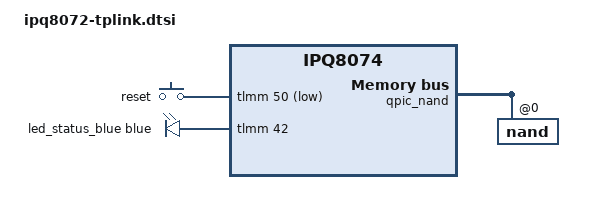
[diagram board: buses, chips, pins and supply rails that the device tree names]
// SPDX-License-Identifier: GPL-2.0-or-later OR MIT

#include "ipq8074.dtsi"
#include "ipq8074-ess.dtsi"
#include "ipq8074-nss.dtsi"
#include "ipq8074-common.dtsi"
#include "ipq8074-hk-cpu.dtsi"

#include <dt-bindings/gpio/gpio.h>
#include <dt-bindings/input/input.h>
#include <dt-bindings/leds/common.h>

/ {
	aliases {
		serial0 = &blsp1_uart5;

		led-boot = &led_status_blue;
		led-failsafe = &led_status_blue;
		led-running = &led_status_blue;
		led-upgrade = &led_status_blue;
	};

	chosen {
		stdout-path = "serial0,115200n8";
		bootargs-append = " root=/dev/ubiblock0_1";
	};

	keys {
		compatible = "gpio-keys";

		reset {
			label = "reset";
			gpios = <&tlmm 50 GPIO_ACTIVE_LOW>;
			linux,code = <KEY_RESTART>;
		};
	};

	leds {
		compatible = "gpio-leds";

		led_status_blue: status-blue {
			function = LED_FUNCTION_STATUS;
			gpios = <&tlmm 42 GPIO_ACTIVE_HIGH>;
			color = <LED_COLOR_ID_BLUE>;
		};
	};
};

&qpic_nand {
	status = "okay";

	nand@0 {
		reg = <0>;

		nand-ecc-strength = <4>;
		nand-ecc-step-size = <512>;
		nand-bus-width = <8>;

		partitions {
			compatible = "qcom,smem-part";
		};
	};
};

&edma {
	status = "okay";
};
